# nrf9220_secure register map
Vendor: Nordic Semiconductor; Series: nRF92; File version: 1
CPU: CM33 r0p4, little endian, MPU, no FPU, 3 interrupt priority bits, 480 interrupts, 8 SAU regions
Registers are 32-bit, read-write, reset 0x0 unless marked. A register's access mark holds for its fields unless they carry their own. Offsets are from the block's base; [hi:lo] are bit positions; lines under a group give offsets from that group; {n}, {i} and the like mark numbered series; 'fields as' and 'values as' point back to an identical list.

## SICR_S (part 2 of 2) — Secure Information Configuration Registers
Base 0x0E000000
0x1500 AROT group — Interface used by the secure domain firmware to extend the RoT to the other local domains and store information on configuration of debug access ports, CTRL-AP methods, and other platfrom security related configurations per domain. These registers are only accessed the secure domain firmware. Any operations related to the local domains must be requested via the secure domain firmware API.
  0x00 SECURE group — Unspecified
    {0x0+0x60*k} OEMPUBKEY[{k}] (k=0..2) group — The public key used by the top level SUIT manifest. The public key is stored as additional authenticated data (AAD) in unencrypted form using an AEAD scheme realized by AES-256 GCM mode, with the secure domain KEK used as a secret key. The initialization vector is provided in NONCE register. Key attributes from ATTR register shall be used as an additional authenticated data (AAD) in AEAD. The content of PUBKEY registers shall be used as an additional authenticated data (AAD) in AEAD.
      0x00 NONCE — Description cluster: The initialization vector of the encryption algorithm used to protect the top level SUIT manifest public key generation [n].
        [31:0] VALUE — Value of nonce used by AEAD.
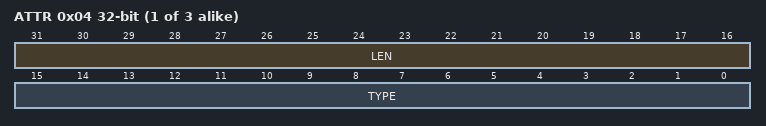
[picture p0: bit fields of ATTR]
      0x04 ATTR — Description cluster: The attributes of the local domain firmware master encryption key generation [n]. This field is used as an additional authenticated data (AAD) in AEAD.
        [31:16] LEN — Length of the key in bits.
        [15:0] TYPE — Type of the key. This field should follow the key type encoding from PSA Crypto API v1.2.1.
      {0x8+4l} PUBKEY[{l}] (l=0..15) — Description collection: The top level SUIT manifest public key generation [n]. This field is used as an additional authenticated data (AAD) in AEAD.
        [31:0] VALUE — Value for word [o] in the key value [n].
      {0x48+4l} MAC[{l}] (l=0..3) — Description collection: The authentication tag of the top level SUIT manifest public key generation [n].
        [31:0] VALUE — The word [o] of the authentication tag.
      {0x58+4l} RFU[{l}] (l=0..1) — Description collection:
        [31:0] VALUE — RFU word [o].
    0x120 PERSONALIZATION group — The device unique pad used as part of a personalization string during IKG key generation.
      {0x0+4l} PAD[{l}] (l=0..3) — Description collection: The device unique pad.
        [31:0] VALUE — Value for word [n] in the unique pad.
    0x130 DATAPROTECTION group — Elements used for validation of data provisioned onto a device by the local domain.
      0x00 UICR group — Authentication tag used for validation of the content of the UICRs. The UICRs content provides information about a domain peripherals associations and memory layout configuration. It is stored in an unencrypted form in a dedicated memory location. A validation shall be performed using an AEAD scheme realized by AES-256 GCM mode, with the domain KEK used as a secret key and UICR content used as additional authenticated data (AAD). The initialization vector is provided in NONCE register.
        0x00 NONCE — The initialization vector of the encryption algorithm used to protect the domain UICRs content.
          [31:0] VALUE — Value of nonce used by AEAD.
        {0x4+4m} MAC[{m}] (m=0..3) — Description collection: The authentication tag of the domain UICRs.
          [31:0] VALUE — The word [n] of the authentication tag.
        {0x14+4m} RFU[{m}] (m=0..2) — Description collection:
          [31:0] VALUE — RFU word [n].
  0x400 APPLICATION group — Unspecified
    {0x0+0x40*k} FWENC[{k}] (k=0..1) group — Local domain firmware master encryption key. The key is stored in an encrypted then authenticated form using an AEAD scheme realized by AES-256 GCM mode, with the local domain KEK used as a secret key. The initialization vector is provided in NONCE register. Key attributes from ATTR register shall be used as an additional authenticated data (AAD) in AEAD.
      0x00 NONCE — Description cluster: The initialization vector of the encryption algorithm used to protect the local domain firmware master encryption key generation [n].
        [31:0] VALUE — Value of nonce used by AEAD.
      0x04 ATTR — Description cluster: The attributes of the local domain firmware master encryption key generation [n]. This field is used as an additional authenticated data (AAD) in AEAD.
        fields as AROT.SECURE.OEMPUBKEY[0].ATTR
      {0x8+4l} CIPHERTEXT[{l}] (l=0..7) — Description collection: The encrypted local domain firmware master encryption key generation [n].
        [31:0] VALUE — Value for word [o] in the key value [n].
      {0x28+4l} MAC[{l}] (l=0..3) — Description collection: The authentication tag of the local domain firmware master encryption key generation [n].
        [31:0] VALUE — The word [o] of the authentication tag.
      {0x38+4l} RFU[{l}] (l=0..1) — Description collection:
        [31:0] VALUE — RFU word [o].
    {0x80+0x60*k} AUTHDEBUGKEY[{k}] (k=0..2) group — Local domain authenticated debug access public key. The public key is stored as additional authenticated data (AAD) in unencrypted form using an AEAD scheme realized by AES-256 GCM mode, with the local domain KEK used as a secret key. The initialization vector is provided in NONCE register. Key attributes from ATTR register shall be used as an additional authenticated data (AAD) in AEAD. The content of PUBKEY registers shall be used as an additional authenticated data (AAD) in AEAD.
      0x00 NONCE — Description cluster: The initialization vector of the encryption algorithm used to protect the local domain authenticated debug access public key generation [n].
        [31:0] VALUE — Value of nonce used by AEAD.
      0x04 ATTR — Description cluster: The attributes of the local domain firmware master encryption key generation [n]. This field is used as an additional authenticated data (AAD) in AEAD.
        fields as AROT.SECURE.OEMPUBKEY[0].ATTR
      {0x8+4l} PUBKEY[{l}] (l=0..15) — Description collection: The local domain authenticated debug access public key generation [n].
        [31:0] VALUE — Value for word [o] in the key value [n].
      {0x48+4l} MAC[{l}] (l=0..3) — Description collection: The authentication tag of the local domain authenticated debug access public key generation [n].
        [31:0] VALUE — The word [o] of the authentication tag.
      {0x58+4l} RFU[{l}] (l=0..1) — Description collection:
        [31:0] VALUE — RFU word [o].
    {0x1A0+0x60*k} SUITPUBKEY[{k}] (k=0..2) group — Public key used by the local domain SUIT manifest. The public key is stored as additional authenticated data (AAD) in unencrypted form using an AEAD scheme realized by AES-256 GCM mode, with the local domain KEK used as a secret key. The initialization vector is provided in NONCE register. Key attributes from ATTR register shall be used as an additional authenticated data (AAD) in AEAD. The content of PUBKEY registers shall be used as an additional authenticated data (AAD) in AEAD.
      0x00 NONCE — Description cluster: The initialization vector of the encryption algorithm used to protect the local domain SUIT manifest public key generation [n].
        [31:0] VALUE — Value of nonce used by AEAD.
      0x04 ATTR — Description cluster: The attributes of the local domain firmware master encryption key generation [n]. This field is used as an additional authenticated data (AAD) in AEAD.
        fields as AROT.SECURE.OEMPUBKEY[0].ATTR
      {0x8+4l} PUBKEY[{l}] (l=0..15) — Description collection: The local domain SUIT manifest public key generation [n].
        [31:0] VALUE — Value for word [o] in the key value [n].
      {0x48+4l} MAC[{l}] (l=0..3) — Description collection: The authentication tag of the local domain SUIT manifest public key generation [n].
        [31:0] VALUE — The word [o] of the authentication tag.
      {0x58+4l} RFU[{l}] (l=0..1) — Description collection:
        [31:0] VALUE — RFU word [o].
    0x2C0 DATAPROTECTION group — Elements used for validation of data provisioned onto a device by the local domain.
      0x00 UICR group — Authentication tag used for validation of the content of the UICRs. The UICRs content provides information about a domain peripherals associations and memory layout configuration. It is stored in an unencrypted form in a dedicated memory location. A validation shall be performed using an AEAD scheme realized by AES-256 GCM mode, with the domain KEK used as a secret key and UICR content used as additional authenticated data (AAD). The initialization vector is provided in NONCE register.
        0x00 NONCE — The initialization vector of the encryption algorithm used to protect the domain UICRs content.
          [31:0] VALUE — Value of nonce used by AEAD.
        {0x4+4m} MAC[{m}] (m=0..3) — Description collection: The authentication tag of the domain UICRs.
          [31:0] VALUE — The word [n] of the authentication tag.
        {0x14+4m} RFU[{m}] (m=0..2) — Description collection:
          [31:0] VALUE — RFU word [n].
    0x2E0 DOMAINSTATE group — Registers holding the information regarding the local domain state.
      {0x0+4l} RFU[{l}] (l=0..2) — Description collection:
        [31:0] VALUE — RFU word [n].
      0x0C LCS — The local domain lifecycle state as determined by the URoT.
        [31:0] STATE — The local domain lifecycle state.
          0x3590FCC5=AssemblyAndTest (The local domain assets are installed in this state. This includes the optional local domain ARoT (its secure program).); 0xF6852179=ARoTProvisioning (The optional local domain ARoT is provisioned in this state.); 0x9F6B5F01=Secured (The local domain assets are provisioned and secured.)
  0x800 RADIO group — Unspecified
    {0x0+0x40*k} FWENC[{k}] (k=0..1) group — Local domain firmware master encryption key. The key is stored in an encrypted then authenticated form using an AEAD scheme realized by AES-256 GCM mode, with the local domain KEK used as a secret key. The initialization vector is provided in NONCE register. Key attributes from ATTR register shall be used as an additional authenticated data (AAD) in AEAD.
      0x00 NONCE — Description cluster: The initialization vector of the encryption algorithm used to protect the local domain firmware master encryption key generation [n].
        [31:0] VALUE — Value of nonce used by AEAD.
      0x04 ATTR — Description cluster: The attributes of the local domain firmware master encryption key generation [n]. This field is used as an additional authenticated data (AAD) in AEAD.
        fields as AROT.SECURE.OEMPUBKEY[0].ATTR
      {0x8+4l} CIPHERTEXT[{l}] (l=0..7) — Description collection: The encrypted local domain firmware master encryption key generation [n].
        [31:0] VALUE — Value for word [o] in the key value [n].
      {0x28+4l} MAC[{l}] (l=0..3) — Description collection: The authentication tag of the local domain firmware master encryption key generation [n].
        [31:0] VALUE — The word [o] of the authentication tag.
      {0x38+4l} RFU[{l}] (l=0..1) — Description collection:
        [31:0] VALUE — RFU word [o].
    {0x80+0x60*k} AUTHDEBUGKEY[{k}] (k=0..2) group — Local domain authenticated debug access public key. The public key is stored as additional authenticated data (AAD) in unencrypted form using an AEAD scheme realized by AES-256 GCM mode, with the local domain KEK used as a secret key. The initialization vector is provided in NONCE register. Key attributes from ATTR register shall be used as an additional authenticated data (AAD) in AEAD. The content of PUBKEY registers shall be used as an additional authenticated data (AAD) in AEAD.
      0x00 NONCE — Description cluster: The initialization vector of the encryption algorithm used to protect the local domain authenticated debug access public key generation [n].
        [31:0] VALUE — Value of nonce used by AEAD.
      0x04 ATTR — Description cluster: The attributes of the local domain firmware master encryption key generation [n]. This field is used as an additional authenticated data (AAD) in AEAD.
        fields as AROT.SECURE.OEMPUBKEY[0].ATTR
      {0x8+4l} PUBKEY[{l}] (l=0..15) — Description collection: The local domain authenticated debug access public key generation [n].
        [31:0] VALUE — Value for word [o] in the key value [n].
      {0x48+4l} MAC[{l}] (l=0..3) — Description collection: The authentication tag of the local domain authenticated debug access public key generation [n].
        [31:0] VALUE — The word [o] of the authentication tag.
      {0x58+4l} RFU[{l}] (l=0..1) — Description collection:
        [31:0] VALUE — RFU word [o].
    {0x1A0+0x60*k} SUITPUBKEY[{k}] (k=0..2) group — Public key used by the local domain SUIT manifest. The public key is stored as additional authenticated data (AAD) in unencrypted form using an AEAD scheme realized by AES-256 GCM mode, with the local domain KEK used as a secret key. The initialization vector is provided in NONCE register. Key attributes from ATTR register shall be used as an additional authenticated data (AAD) in AEAD. The content of PUBKEY registers shall be used as an additional authenticated data (AAD) in AEAD.
      0x00 NONCE — Description cluster: The initialization vector of the encryption algorithm used to protect the local domain SUIT manifest public key generation [n].
        [31:0] VALUE — Value of nonce used by AEAD.
      0x04 ATTR — Description cluster: The attributes of the local domain firmware master encryption key generation [n]. This field is used as an additional authenticated data (AAD) in AEAD.
        fields as AROT.SECURE.OEMPUBKEY[0].ATTR
      {0x8+4l} PUBKEY[{l}] (l=0..15) — Description collection: The local domain SUIT manifest public key generation [n].
        [31:0] VALUE — Value for word [o] in the key value [n].
      {0x48+4l} MAC[{l}] (l=0..3) — Description collection: The authentication tag of the local domain SUIT manifest public key generation [n].
        [31:0] VALUE — The word [o] of the authentication tag.
      {0x58+4l} RFU[{l}] (l=0..1) — Description collection:
        [31:0] VALUE — RFU word [o].
    0x2C0 DATAPROTECTION group — Elements used for validation of data provisioned onto a device by the local domain.
      0x00 UICR group — Authentication tag used for validation of the content of the UICRs. The UICRs content provides information about a domain peripherals associations and memory layout configuration. It is stored in an unencrypted form in a dedicated memory location. A validation shall be performed using an AEAD scheme realized by AES-256 GCM mode, with the domain KEK used as a secret key and UICR content used as additional authenticated data (AAD). The initialization vector is provided in NONCE register.
        0x00 NONCE — The initialization vector of the encryption algorithm used to protect the domain UICRs content.
          [31:0] VALUE — Value of nonce used by AEAD.
        {0x4+4m} MAC[{m}] (m=0..3) — Description collection: The authentication tag of the domain UICRs.
          [31:0] VALUE — The word [n] of the authentication tag.
        {0x14+4m} RFU[{m}] (m=0..2) — Description collection:
          [31:0] VALUE — RFU word [n].
    0x2E0 DOMAINSTATE group — Registers holding the information regarding the local domain state.
      {0x0+4l} RFU[{l}] (l=0..2) — Description collection:
        [31:0] VALUE — RFU word [n].
      0x0C LCS — The local domain lifecycle state as determined by the URoT.
        fields as AROT.APPLICATION.DOMAINSTATE.LCS
  0xC00 CELLULARCORE group — Unspecified
    {0x0+0x40*k} FWENC[{k}] (k=0..1) group — Local domain firmware master encryption key. The key is stored in an encrypted then authenticated form using an AEAD scheme realized by AES-256 GCM mode, with the local domain KEK used as a secret key. The initialization vector is provided in NONCE register. Key attributes from ATTR register shall be used as an additional authenticated data (AAD) in AEAD.
      0x00 NONCE — Description cluster: The initialization vector of the encryption algorithm used to protect the local domain firmware master encryption key generation [n].
        [31:0] VALUE — Value of nonce used by AEAD.
      0x04 ATTR — Description cluster: The attributes of the local domain firmware master encryption key generation [n]. This field is used as an additional authenticated data (AAD) in AEAD.
        fields as AROT.SECURE.OEMPUBKEY[0].ATTR
      {0x8+4l} CIPHERTEXT[{l}] (l=0..7) — Description collection: The encrypted local domain firmware master encryption key generation [n].
        [31:0] VALUE — Value for word [o] in the key value [n].
      {0x28+4l} MAC[{l}] (l=0..3) — Description collection: The authentication tag of the local domain firmware master encryption key generation [n].
        [31:0] VALUE — The word [o] of the authentication tag.
      {0x38+4l} RFU[{l}] (l=0..1) — Description collection:
        [31:0] VALUE — RFU word [o].
    {0x80+0x60*k} AUTHDEBUGKEY[{k}] (k=0..2) group — Local domain authenticated debug access public key. The public key is stored as additional authenticated data (AAD) in unencrypted form using an AEAD scheme realized by AES-256 GCM mode, with the local domain KEK used as a secret key. The initialization vector is provided in NONCE register. Key attributes from ATTR register shall be used as an additional authenticated data (AAD) in AEAD. The content of PUBKEY registers shall be used as an additional authenticated data (AAD) in AEAD.
      0x00 NONCE — Description cluster: The initialization vector of the encryption algorithm used to protect the local domain authenticated debug access public key generation [n].
        [31:0] VALUE — Value of nonce used by AEAD.
      0x04 ATTR — Description cluster: The attributes of the local domain firmware master encryption key generation [n]. This field is used as an additional authenticated data (AAD) in AEAD.
        fields as AROT.SECURE.OEMPUBKEY[0].ATTR
      {0x8+4l} PUBKEY[{l}] (l=0..15) — Description collection: The local domain authenticated debug access public key generation [n].
        [31:0] VALUE — Value for word [o] in the key value [n].
      {0x48+4l} MAC[{l}] (l=0..3) — Description collection: The authentication tag of the local domain authenticated debug access public key generation [n].
        [31:0] VALUE — The word [o] of the authentication tag.
      {0x58+4l} RFU[{l}] (l=0..1) — Description collection:
        [31:0] VALUE — RFU word [o].
    {0x1A0+0x60*k} SUITPUBKEY[{k}] (k=0..2) group — Public key used by the local domain SUIT manifest. The public key is stored as additional authenticated data (AAD) in unencrypted form using an AEAD scheme realized by AES-256 GCM mode, with the local domain KEK used as a secret key. The initialization vector is provided in NONCE register. Key attributes from ATTR register shall be used as an additional authenticated data (AAD) in AEAD. The content of PUBKEY registers shall be used as an additional authenticated data (AAD) in AEAD.
      0x00 NONCE — Description cluster: The initialization vector of the encryption algorithm used to protect the local domain SUIT manifest public key generation [n].
        [31:0] VALUE — Value of nonce used by AEAD.
      0x04 ATTR — Description cluster: The attributes of the local domain firmware master encryption key generation [n]. This field is used as an additional authenticated data (AAD) in AEAD.
        fields as AROT.SECURE.OEMPUBKEY[0].ATTR
      {0x8+4l} PUBKEY[{l}] (l=0..15) — Description collection: The local domain SUIT manifest public key generation [n].
        [31:0] VALUE — Value for word [o] in the key value [n].
      {0x48+4l} MAC[{l}] (l=0..3) — Description collection: The authentication tag of the local domain SUIT manifest public key generation [n].
        [31:0] VALUE — The word [o] of the authentication tag.
      {0x58+4l} RFU[{l}] (l=0..1) — Description collection:
        [31:0] VALUE — RFU word [o].
    0x2C0 DATAPROTECTION group — Elements used for validation of data provisioned onto a device by the local domain.
      0x00 UICR group — Authentication tag used for validation of the content of the UICRs. The UICRs content provides information about a domain peripherals associations and memory layout configuration. It is stored in an unencrypted form in a dedicated memory location. A validation shall be performed using an AEAD scheme realized by AES-256 GCM mode, with the domain KEK used as a secret key and UICR content used as additional authenticated data (AAD). The initialization vector is provided in NONCE register.
        0x00 NONCE — The initialization vector of the encryption algorithm used to protect the domain UICRs content.
          [31:0] VALUE — Value of nonce used by AEAD.
        {0x4+4m} MAC[{m}] (m=0..3) — Description collection: The authentication tag of the domain UICRs.
          [31:0] VALUE — The word [n] of the authentication tag.
        {0x14+4m} RFU[{m}] (m=0..2) — Description collection:
          [31:0] VALUE — RFU word [n].
    0x2E0 DOMAINSTATE group — Registers holding the information regarding the local domain state.
      {0x0+4l} RFU[{l}] (l=0..2) — Description collection:
        [31:0] VALUE — RFU word [n].
      0x0C LCS — The local domain lifecycle state as determined by the URoT.
        fields as AROT.APPLICATION.DOMAINSTATE.LCS
  0x1000 WIFICORE group — Unspecified
    {0x0+0x40*k} FWENC[{k}] (k=0..1) group — Local domain firmware master encryption key. The key is stored in an encrypted then authenticated form using an AEAD scheme realized by AES-256 GCM mode, with the local domain KEK used as a secret key. The initialization vector is provided in NONCE register. Key attributes from ATTR register shall be used as an additional authenticated data (AAD) in AEAD.
      0x00 NONCE — Description cluster: The initialization vector of the encryption algorithm used to protect the local domain firmware master encryption key generation [n].
        [31:0] VALUE — Value of nonce used by AEAD.
      0x04 ATTR — Description cluster: The attributes of the local domain firmware master encryption key generation [n]. This field is used as an additional authenticated data (AAD) in AEAD.
        fields as AROT.SECURE.OEMPUBKEY[0].ATTR
      {0x8+4l} CIPHERTEXT[{l}] (l=0..7) — Description collection: The encrypted local domain firmware master encryption key generation [n].
        [31:0] VALUE — Value for word [o] in the key value [n].
      {0x28+4l} MAC[{l}] (l=0..3) — Description collection: The authentication tag of the local domain firmware master encryption key generation [n].
        [31:0] VALUE — The word [o] of the authentication tag.
      {0x38+4l} RFU[{l}] (l=0..1) — Description collection:
        [31:0] VALUE — RFU word [o].
    {0x80+0x60*k} AUTHDEBUGKEY[{k}] (k=0..2) group — Local domain authenticated debug access public key. The public key is stored as additional authenticated data (AAD) in unencrypted form using an AEAD scheme realized by AES-256 GCM mode, with the local domain KEK used as a secret key. The initialization vector is provided in NONCE register. Key attributes from ATTR register shall be used as an additional authenticated data (AAD) in AEAD. The content of PUBKEY registers shall be used as an additional authenticated data (AAD) in AEAD.
      0x00 NONCE — Description cluster: The initialization vector of the encryption algorithm used to protect the local domain authenticated debug access public key generation [n].
        [31:0] VALUE — Value of nonce used by AEAD.
      0x04 ATTR — Description cluster: The attributes of the local domain firmware master encryption key generation [n]. This field is used as an additional authenticated data (AAD) in AEAD.
        fields as AROT.SECURE.OEMPUBKEY[0].ATTR
      {0x8+4l} PUBKEY[{l}] (l=0..15) — Description collection: The local domain authenticated debug access public key generation [n].
        [31:0] VALUE — Value for word [o] in the key value [n].
      {0x48+4l} MAC[{l}] (l=0..3) — Description collection: The authentication tag of the local domain authenticated debug access public key generation [n].
        [31:0] VALUE — The word [o] of the authentication tag.
      {0x58+4l} RFU[{l}] (l=0..1) — Description collection:
        [31:0] VALUE — RFU word [o].
    {0x1A0+0x60*k} SUITPUBKEY[{k}] (k=0..2) group — Public key used by the local domain SUIT manifest. The public key is stored as additional authenticated data (AAD) in unencrypted form using an AEAD scheme realized by AES-256 GCM mode, with the local domain KEK used as a secret key. The initialization vector is provided in NONCE register. Key attributes from ATTR register shall be used as an additional authenticated data (AAD) in AEAD. The content of PUBKEY registers shall be used as an additional authenticated data (AAD) in AEAD.
      0x00 NONCE — Description cluster: The initialization vector of the encryption algorithm used to protect the local domain SUIT manifest public key generation [n].
        [31:0] VALUE — Value of nonce used by AEAD.
      0x04 ATTR — Description cluster: The attributes of the local domain firmware master encryption key generation [n]. This field is used as an additional authenticated data (AAD) in AEAD.
        fields as AROT.SECURE.OEMPUBKEY[0].ATTR
      {0x8+4l} PUBKEY[{l}] (l=0..15) — Description collection: The local domain SUIT manifest public key generation [n].
        [31:0] VALUE — Value for word [o] in the key value [n].
      {0x48+4l} MAC[{l}] (l=0..3) — Description collection: The authentication tag of the local domain SUIT manifest public key generation [n].
        [31:0] VALUE — The word [o] of the authentication tag.
      {0x58+4l} RFU[{l}] (l=0..1) — Description collection:
        [31:0] VALUE — RFU word [o].
    0x2C0 DATAPROTECTION group — Elements used for validation of data provisioned onto a device by the local domain.
      0x00 UICR group — Authentication tag used for validation of the content of the UICRs. The UICRs content provides information about a domain peripherals associations and memory layout configuration. It is stored in an unencrypted form in a dedicated memory location. A validation shall be performed using an AEAD scheme realized by AES-256 GCM mode, with the domain KEK used as a secret key and UICR content used as additional authenticated data (AAD). The initialization vector is provided in NONCE register.
        0x00 NONCE — The initialization vector of the encryption algorithm used to protect the domain UICRs content.
          [31:0] VALUE — Value of nonce used by AEAD.
        {0x4+4m} MAC[{m}] (m=0..3) — Description collection: The authentication tag of the domain UICRs.
          [31:0] VALUE — The word [n] of the authentication tag.
        {0x14+4m} RFU[{m}] (m=0..2) — Description collection:
          [31:0] VALUE — RFU word [n].
    0x2E0 DOMAINSTATE group — Registers holding the information regarding the local domain state.
      {0x0+4l} RFU[{l}] (l=0..2) — Description collection:
        [31:0] VALUE — RFU word [n].
      0x0C LCS — The local domain lifecycle state as determined by the URoT.
        fields as AROT.APPLICATION.DOMAINSTATE.LCS
